# STM32C071 register map
File version: 1.1
CPU: CM0+ r0p0, little endian, MPU, no FPU, 2 interrupt priority bits
Registers are 32-bit, read-write, reset 0x0 unless marked. A register's access mark holds for its fields unless they carry their own. Offsets are from the block's base; [hi:lo] are bit positions; lines under a group give offsets from that group; {n}, {i} and the like mark numbered series; 'fields as' and 'values as' point back to an identical list.

## DMA — DMA register bank
Base 0x40020000
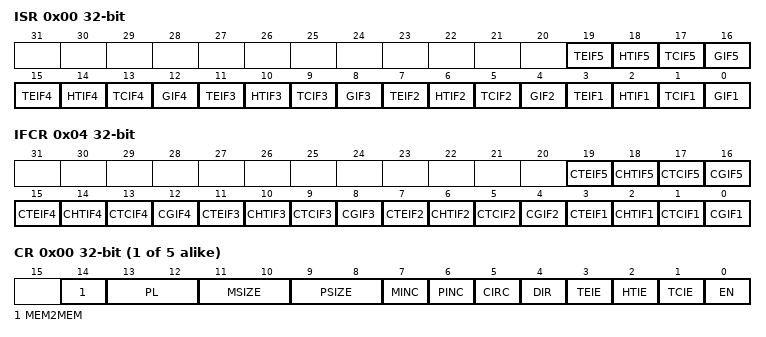
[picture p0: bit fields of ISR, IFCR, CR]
0x00 ISR ro — DMA interrupt status register
  [4n-1] TEIF{n} (n=1..5) — Channel {n} Transfer Error flag
    0=NoError (No transfer error); 1=Error (A transfer error has occured)
  [4n-2] HTIF{n} (n=1..5) — Channel {n} Half Transfer Complete flag
    0=NotHalf (No half transfer event); 1=Half (A half transfer event has occured)
  [4n-3] TCIF{n} (n=1..5) — Channel {n} Transfer Complete flag
    0=NotComplete (No transfer complete event); 1=Complete (A transfer complete event has occured)
  [4n-4] GIF{n} (n=1..5) — Channel {n} Global interrupt flag
    0=NoEvent (No transfer error, half event, complete event); 1=Event (A transfer error, half event or complete event has occured)
0x04 IFCR wo — DMA interrupt flag clear register
  [4n-1] CTEIF{n} (n=1..5) — Channel {n} Transfer Error clear
    1=Clears the TEIF flag in the ISR register
  [4n-2] CHTIF{n} (n=1..5) — Channel {n} Half Transfer clear
    1=Clears the HTIF flag in the ISR register
  [4n-3] CTCIF{n} (n=1..5) — Channel {n} Transfer Complete clear
    1=Clears the TCIF flag in the ISR register
  [4n-4] CGIF{n} (n=1..5) — Channel {n} Global interrupt clear
    1=Clears the GIF, TEIF, HTIF, TCIF flags in the ISR register
0x08 CH{i} (i=1..5; step 0x14) group — Channel cluster: CCR?, CNDTR?, CPAR?, and CMAR? registers
  0x00 CR — DMA channel 1 configuration register
    [14] MEM2MEM — Memory-to-memory mode Note: This bit is set and cleared by software. It must not be written when the channel is enabled (EN = 1). It is read-only when the channel is enabled (EN = 1).
      0=Disabled (Memory to memory mode disabled); 1=Enabled (Memory to memory mode enabled)
    [13:12] PL — Priority level Note: This bitfield is set and cleared by software. It must not be written when the channel is enabled (EN = 1). It is read-only when the channel is enabled (EN = 1).
      0=Low (Low priority); 1=Medium priority; 2=High priority; 3=Very high priority
    [11:10] MSIZE — Memory size Defines the data size of each DMA transfer to the identified memory. In memory-to-memory mode, this bitfield identifies the memory source if DIR = 1 and the memory destination if DIR = 0. In peripheral-to-peripheral mode, this bitfield identifies the peripheral source if DIR = 1 and the peripheral destination if DIR = 0. Note: This bitfield is set and cleared by software. It must not be written when the channel is enabled (EN = 1). It is read-only when the channel is enabled (EN = 1).
      0=Bits8 (8-bit size); 1=Bits16 (16-bit size); 2=Bits32 (32-bit size)
    [9:8] PSIZE — Peripheral size Defines the data size of each DMA transfer to the identified peripheral. In memory-to-memory mode, this bitfield identifies the memory destination if DIR = 1 and the memory source if DIR = 0. In peripheral-to-peripheral mode, this bitfield identifies the peripheral destination if DIR = 1 and the peripheral source if DIR = 0. Note: This bitfield is set and cleared by software. It must not be written when the channel is enabled (EN = 1). It is read-only when the channel is enabled (EN = 1).
      values as MSIZE
    [7] MINC — Memory increment mode Defines the increment mode for each DMA transfer to the identified memory. In memory-to-memory mode, this bit identifies the memory source if DIR = 1 and the memory destination if DIR = 0. In peripheral-to-peripheral mode, this bit identifies the peripheral source if DIR = 1 and the peripheral destination if DIR = 0. Note: This bit is set and cleared by software. It must not be written when the channel is enabled (EN = 1). It is read-only when the channel is enabled (EN = 1).
      0=Disabled (Increment mode disabled); 1=Enabled (Increment mode enabled)
    [6] PINC — Peripheral increment mode Defines the increment mode for each DMA transfer to the identified peripheral. n memory-to-memory mode, this bit identifies the memory destination if DIR = 1 and the memory source if DIR = 0. In peripheral-to-peripheral mode, this bit identifies the peripheral destination if DIR = 1 and the peripheral source if DIR = 0. Note: This bit is set and cleared by software. It must not be written when the channel is enabled (EN = 1). It is read-only when the channel is enabled (EN = 1).
      values as MINC
    [5] CIRC — Circular mode Note: This bit is set and cleared by software. It must not be written when the channel is enabled (EN = 1). It is not read-only when the channel is enabled (EN = 1).
      0=Disabled (Circular buffer disabled); 1=Enabled (Circular buffer enabled)
    [4] DIR — Data transfer direction This bit must be set only in memory-to-peripheral and peripheral-to-memory modes. Source attributes are defined by PSIZE and PINC, plus the DMA_CPARx register. This is still valid in a memory-to-memory mode. Destination attributes are defined by MSIZE and MINC, plus the DMA_CMARx register. This is still valid in a peripheral-to-peripheral mode. Destination attributes are defined by PSIZE and PINC, plus the DMA_CPARx register. This is still valid in a memory-to-memory mode. Source attributes are defined by MSIZE and MINC, plus the DMA_CMARx register. This is still valid in a peripheral-to-peripheral mode. Note: This bit is set and cleared by software. It must not be written when the channel is enabled (EN = 1). It is read-only when the channel is enabled (EN = 1).
      0=FromPeripheral (Read from peripheral); 1=FromMemory (Read from memory)
    [3] TEIE — Transfer error interrupt enable Note: This bit is set and cleared by software. It must not be written when the channel is enabled (EN = 1). It is not read-only when the channel is enabled (EN = 1).
      0=Disabled (Transfer Error interrupt disabled); 1=Enabled (Transfer Error interrupt enabled)
    [2] HTIE — Half transfer interrupt enable Note: This bit is set and cleared by software. It must not be written when the channel is enabled (EN = 1). It is not read-only when the channel is enabled (EN = 1).
      0=Disabled (Half Transfer interrupt disabled); 1=Enabled (Half Transfer interrupt enabled)
    [1] TCIE — Transfer complete interrupt enable Note: This bit is set and cleared by software. It must not be written when the channel is enabled (EN = 1). It is not read-only when the channel is enabled (EN = 1).
      0=Disabled (Transfer Complete interrupt disabled); 1=Enabled (Transfer Complete interrupt enabled)
    [0] EN — Channel enable When a channel transfer error occurs, this bit is cleared by hardware. It can not be set again by software (channel x re-activated) until the TEIFx bit of the DMA_ISR register is cleared (by setting the CTEIFx bit of the DMA_IFCR register). Note: This bit is set and cleared by software.
      0=Disabled (Channel disabled); 1=Enabled (Channel enabled)
  0x04 NDTR — DMA channel 1 number of data to transfer register
    [15:0] NDT — Number of data to transfer (0 to 2<sup>16</sup> - 1) This bitfield is updated by hardware when the channel is enabled: It is decremented after each single DMA read followed by write transfer, indicating the remaining amount of data items to transfer. It is kept at zero when the programmed amount of data to transfer is reached, if the channel is not in circular mode (CIRC = 0 in the DMA_CCRx register). It is reloaded automatically by the previously programmed value, when the transfer is complete, if the channel is in circular mode (CIRC = 1). If this bitfield is zero, no transfer can be served whatever the channel status (enabled or not). Note: This bitfield is set and cleared by software. It must not be written when the channel is enabled (EN = 1). It is read-only when the channel is enabled (EN = 1).
  0x08 PAR — DMA channel 1 peripheral address register
    [31:0] PA — Peripheral address It contains the base address of the peripheral data register from/to which the data is read/written. When PSIZE[1:0] = 01 (16 bits), bit 0 of PA[31:0] is ignored. Access is automatically aligned to a half-word address. When PSIZE[1:0] = 10 (32 bits), bits 1 and 0 of PA[31:0] are ignored. Access is automatically aligned to a word address. In memory-to-memory mode, this bitfield identifies the memory destination address if DIR = 1 and the memory source address if DIR = 0. In peripheral-to-peripheral mode, this bitfield identifies the peripheral destination address if DIR = 1 and the peripheral source address if DIR = 0. Note: This bitfield is set and cleared by software. It must not be written when the channel is enabled (EN = 1). It is not read-only when the channel is enabled (EN = 1).
  0x0C MAR — DMA channel 1 memory address register
    [31:0] MA — Peripheral address It contains the base address of the memory from/to which the data is read/written. When MSIZE[1:0] = 01 (16 bits), bit 0 of MA[31:0] is ignored. Access is automatically aligned to a half-word address. When MSIZE[1:0] = 10 (32 bits), bits 1 and 0 of MA[31:0] are ignored. Access is automatically aligned to a word address. In memory-to-memory mode, this bitfield identifies the memory source address if DIR = 1 and the memory destination address if DIR = 0. In peripheral-to-peripheral mode, this bitfield identifies the peripheral source address if DIR = 1 and the peripheral destination address if DIR = 0. Note: This bitfield is set and cleared by software. It must not be written when the channel is enabled (EN = 1). It is not read-only when the channel is enabled (EN = 1).
